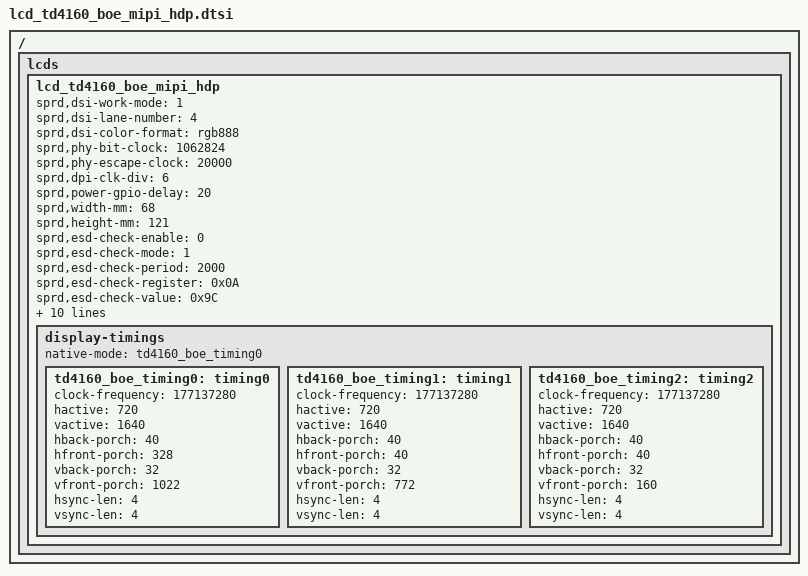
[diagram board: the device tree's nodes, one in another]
// SPDX-License-Identifier: GPL-2.0-only
/*
 * Unisoc td4160 Truly LCD config DTS file
 *
 * Copyright (C) 2021, Unisoc Inc.
 */

/ {
	fragment {
		target-path = "/";
		__overlay__ {
			lcds {
				lcd_td4160_boe_mipi_hdp: lcd_td4160_boe_mipi_hdp {
					sprd,dsi-work-mode = <1>; /* video burst mode*/
					sprd,dsi-lane-number = <4>;
					sprd,dsi-color-format = "rgb888";

					sprd,phy-bit-clock = <1062824>; /* kbps */
					sprd,phy-escape-clock = <20000>;/* kHz */
					sprd,dpi-clk-div = <6>;
					sprd,power-gpio-delay = <20>;/* ms */

					sprd,width-mm = <68>;
					sprd,height-mm = <121>;

					sprd,esd-check-enable = <0>;
					sprd,esd-check-mode = <1>;
					sprd,esd-check-period = <2000>;
					sprd,esd-check-register = <0x0A>;
					sprd,esd-check-value = <0x9C>;

					sprd,reset-on-sequence = <1 10>, <0 5>, <1 5>, <0 5>, <1 20>;
					sprd,reset-off-sequence = <1 5>;

					sprd,use-dcs-write;
					sprd,initial-command = [
						29 00 00 02 B0 00
						29 00 00 07 B6 30 6b 00 86 c3 03
						29 00 00 05 B7 31 00 00 00
						29 00 00 07 B8 00 78 64 10 64 b4
						29 00 00 07 B9 00 78 64 10 64 b4
						29 00 00 07 BA 00 78 64 10 64 b4
						29 00 00 04 BB 00 b4 a0
						29 00 00 04 BC 00 b4 a0
						29 00 00 04 BD 00 b4 a0
						29 00 00 0e BE 07 00 00 00 00 00 00 00 00 00 00 00 00
						29 00 00 19 C0 00 43 24 06 68 00 07 06 94 00 70 00 00 00 00 00 00 00 00 00 00 00 00 00
						29 00 00 28 C1 30 51 50 fa 01 00 00 10 00 00 00 00 40 0f 00 00 00 00 00 00 00 00 00 00 00 00 00 00 00 00 00 00 00 00 00 00 00 00 00
						29 00 00 f5 C2 00 00 52 14 08 10 16 12 00 00 00 52 14 08 10 12 11 00 00 00 00 00 00 00 00 00 00 00 00 00 00 00 00 00 00 00 00 00 00 00 00 00 03 b0 37 10 10 08 09 c1 00 f0 01 00 00 00 08 00 00 00 00 11 00 f0 04 00 00 00 00 00 00 00 00 00 00 00 00 00 00 00 00 00 00 00 00 00 00 00 00 00 00 00 00 11 00 00 00 00 00 00 00 00 00 00 00 00 00 00 00 00 00 00 00 00 00 00 00 00 00 00 00 00 00 00 00 11 00 00 00 00 00 00 00 00 00 00 00 00 00 00 00 00 00 00 00 00 00 00 00 00 00 00 00 00 00 00 00 11 00 00 00 00 00 00 00 00 00 00 00 00 00 00 00 00 00 00 00 00 00 00 00 00 00 00 00 00 00 00 00 00 00 00 00 00 00 00 00 10 00 00 00 00 00 00 00 00 00 00 00 00 00 00 00 02 00 00 00 00 00 00 00 00 00 00 02 00 00 00 00 00 00 00 00 00 00 00 00 00 00 00 00 00 00 00
						29 00 00 6a C3 00 00 38 c1 01 70 0c 00 00 00 20 00 00 00 41 81 01 06 88 00 00 00 20 02 00 00 38 c1 01 70 09 00 00 00 20 01 00 00 38 c1 01 70 09 00 00 00 20 00 00 00 00 08 00 00 00 00 00 00 00 00 00 00 00 00 00 00 00 00 00 00 00 00 00 00 00 00 00 00 00 00 00 00 00 00 00 00 00 00 00 00 00 00 00 00 00 00 00 00 00 00 00 00 00 00 00
						29 00 00 55 C4 00 02 5e 61 00 03 07 1b 1d 1f 21 13 15 17 19 5F 60 02 02 02 02 02 02 02 02 02 02 02 02 60 5F 1a 18 16 14 22 20 1e 1c 08 04 00 61 5e 02 00 00 00 00 00 00 d0 3f 00 d0 3f 00 00 00 00 00 00 00 00 00 00 00 00 00 03 00 03 00 55 55 55 55 55 55 55 55 55 55 55
						29 00 00 06 C5 08 00 00 00 00
						29 00 00 4d C6 00 00 00 00 01 22 04 22 01 00 46 00 00 00 01 00 46 00 01 05 01 0b 01 35 ff 8f 06 07 01 c0 0f 00 00 00 00 00 00 00 00 00 00 00 00 00 00 00 00 00 00 00 00 00 00 20 20 00 00 00 c0 11 00 00 00 10 10 00 00 00 01 00 50 00 33 03 00 00
						29 00 00 1f CB 02 d0 01 80 00 00 00 00 00 00 00 00 00 00 00 00 00 00 00 00 00 00 40 70 00 00 00 00 00 ff
						29 00 00 19 CE 5d 40 43 49 55 62 71 82 94 a8 b9 cb db e9 f5 fc ff 04 00 04 04 00 00 00
						29 00 00 02 CF 00
						29 00 00 15 D0 c1 46 81 66 09 90 00 d5 92 9f 11 46 06 7e 09 08 dc 1b f0 06
						29 00 00 26 D1 CB D8 1b 33 33 17 07 bb 88 78 88 78 00 3b 77 07 3b 30 06 72 33 13 00 d7 0c 77 02 00 18 70 18 77 11 11 11 20 20
						29 00 00 04 D2 00 00 00
						29 00 00 9a D3 00 00 00 00 00 00 00 00 00 ff f7 ff ff f7 ff ff f7 ff ff f7 ff ff f7 ff ff f7 ff ff f7 ff ff f7 ff ff f7 ff ff f7 ff ff f7 ff ff f7 ff ff f7 ff ff f7 ff ff f7 ff ff f7 ff ff f7 ff ff f7 ff ff f7 ff ff f7 ff ff f7 ff ff f7 ff ff f7 ff ff f7 ff ff f7 ff ff f7 ff ff f7 ff ff f7 ff ff f7 ff ff f7 ff ff f7 ff ff f7 ff ff f7 ff ff f7 ff ff f7 ff ff f7 ff ff f7 ff ff f7 ff ff f7 ff ff f7 ff ff f7 ff ff f7 ff ff f7 ff ff f7 ff ff f7 ff ff f7 ff ff f7 ff ff f7 ff
						29 00 00 18 D4 00 00 00 00 00 00 00 00 00 20 00 00 00 00 20 00 00 00 00 00 00 00 00
						29 00 00 2f D7 01 00 12 12 00 47 00 18 00 47 00 18 03 83 80 85 85 85 87 84 45 86 87 80 88 86 89 83 83 87 84 88 8a 0c 0b 0a 0a 0a 07 07 06 06 00 08 0a 0a
						29 00 00 17 D8 40 99 26 ed 16 6c 16 6c 16 6c 00 14 00 14 00 14 01 0c 00 00 01 00
						29 00 00 29 D9 00 02 7f 00 00 00 00 00 00 00 00 00 00 00 00 c0 00 00 00 00 00 00 00 00 00 00 00 00 00 00 00 00 00 00 00 00 00 00 00 00
						29 00 00 05 DD 30 06 23 65
						29 00 00 0f DE 00 00 00 0f ff 00 00 00 00 10 00 00 00 00
						29 00 00 09 E6 00 00 00 00 00 00 00 00
						29 00 00 24 EA 02 07 07 04 80 10 01 00 00 00 00 03 23 00 07 00 ed 00 ed 00 ed 01 28 01 28 00 47 00 47 00 47 01 0f 01 00
						29 00 00 09 EB 09 80 9b 00 00 00 00 00
						29 00 00 18 EC 02 d0 01 70 73 10 01 00 00 00 00 02 2a 00 00 00 00 00 00 00 00 00 00
						29 00 00 22 ED 01 02 00 00 00 00 00 00 69 47 2b 00 00 00 00 00 00 00 00 00 00 00 02 b0 00 00 00 00 00 00 40 10 00
						29 00 00 7a EE 05 00 05 00 00 03 00 00 03 00 00 03 00 00 03 00 00 03 00 00 00 00 00 00 03 00 00 00 00 00 00 03 00 00 00 00 00 00 03 00 00 00 00 00 00 03 40 00 57 00 00 00 00 00 40 03 00 00 00 00 00 00 03 00 00 00 00 05 55 03 00 00 00 00 00 00 03 00 00 03 00 00 03 00 00 03 00 00 03 00 00 03 00 00 03 00 00 00 00 00 00 00 00 00 00 00 00 00 00 00 00 00 00 00 00 00 00 00 00 00 02
						29 00 00 02 B0 03
						29 00 00 02 B0 04
						29 00 00 05 E5 03 00 00 00
						29 00 00 05 D5 01 8C 01 8C
						29 00 00 4d C7 00 00 00 1B 00 4B 00 77 00 C2 00 DB 00 CF 00 DA 00 E0 00 F1 01 05 01 1C 01 3A 01 45 01 7B 02 1A 02 55 02 9D 02 B2 00 00 00 1B 00 4B 00 77 00 C2 00 DB 00 CF 00 DA 00 E0 00 F1 01 05 01 1C 01 3A 01 45 01 7B 02 1A 02 55 02 9D 02 B2
						29 00 00 4d C7 00 00 00 1D 00 5E 00 90 00 E6 01 0B 01 04 01 12 01 19 01 28 01 39 01 4C 01 64 01 66 01 8E 02 26 02 5F 02 9F 02 B2 00 00 00 1D 00 5E 00 90 00 E6 01 0B 01 04 01 12 01 19 01 28 01 39 01 4C 01 64 01 66 01 8E 02 26 02 5F 02 9F 02 B2
						29 00 00 02 B0 00
						29 00 00 02 D6 00
						29 00 00 02 B0 03
						39 00 00 02 51 FF
						39 00 00 02 53 0C
						39 00 00 02 55 00
						29 80 00 02 B0 03
						05 50 00 01 11
						05 32 00 01 29
						];

					sprd,sleep-in-command = [
						13 14 00 01 28
						13 78 00 01 10
						];

					sprd,sleep-out-command = [
						13 78 00 01 11
						13 14 00 01 29
						];

					display-timings {
						native-mode = <&td4160_boe_timing0>;

						td4160_boe_timing0: timing0 {
							clock-frequency = <177137280>;
							hactive = <720>;
							vactive = <1640>;
							hback-porch = <40>;
							hfront-porch = <328>;
							vback-porch = <32>;
							vfront-porch = <1022>;
							hsync-len = <4>;
							vsync-len = <4>;
						};
						td4160_boe_timing1: timing1 {
							clock-frequency = <177137280>;
							hactive = <720>;
							vactive = <1640>;
							hback-porch = <40>;
							hfront-porch = <40>;
							vback-porch = <32>;
							vfront-porch = <772>;
							hsync-len = <4>;
							vsync-len = <4>;
						};
						td4160_boe_timing2: timing2 {
							clock-frequency = <177137280>;
							hactive = <720>;
							vactive = <1640>;
							hback-porch = <40>;
							hfront-porch = <40>;
							vback-porch = <32>;
							vfront-porch = <160>;
							hsync-len = <4>;
							vsync-len = <4>;
						};
					};

				};
			};
		};
	};
};
